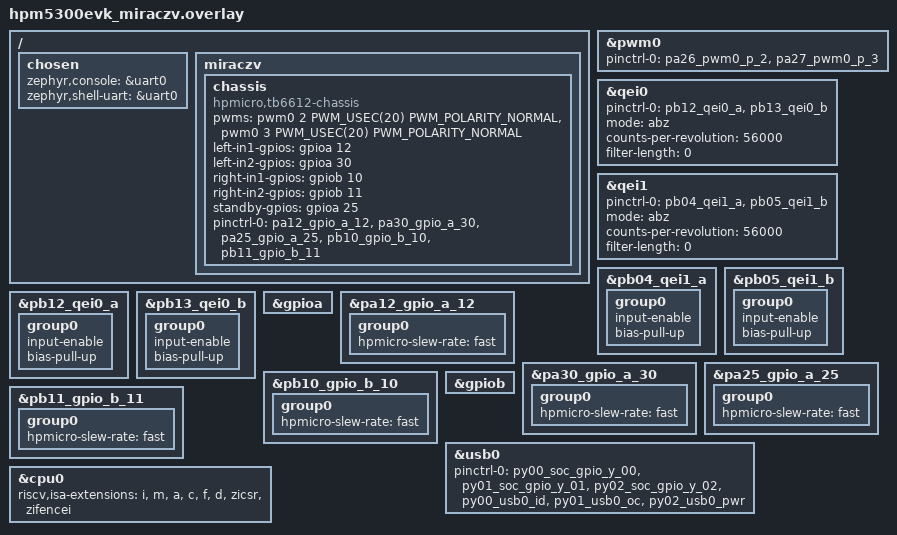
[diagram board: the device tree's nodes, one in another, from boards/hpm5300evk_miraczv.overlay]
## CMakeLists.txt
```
# Copyright (c) 2026 Cody Gu <gujiaqi@iscas.ac.cn>
#
# SPDX-License-Identifier: Apache-2.0

cmake_minimum_required(VERSION 3.20.0)

list(APPEND ZEPHYR_EXTRA_MODULES
  ${CMAKE_CURRENT_SOURCE_DIR}/module
)

list(APPEND DTS_ROOT
  ${CMAKE_CURRENT_SOURCE_DIR}/module
)

find_package(Zephyr REQUIRED HINTS $ENV{ZEPHYR_BASE})
project(MiracZV)

zephyr_include_directories(${CMAKE_CURRENT_SOURCE_DIR}/include)

target_sources(app PRIVATE
  src/main.c
  src/control/controller.c
  src/control/pid.c
  src/control/differential_drive.c
)

if(CONFIG_MIRACZV_MOTOR_TB6612)
  target_sources(app PRIVATE src/platform/tb6612.c)
endif()

if(CONFIG_MIRACZV_ENCODER)
  target_sources(app PRIVATE src/platform/qeiv2_backend.c)
endif()

if(CONFIG_MIRACZV_HID_HOST)
  target_sources(app PRIVATE
    src/platform/hid_controller.c
    src/platform/hid_report.c
  )
  target_include_directories(app PRIVATE ${ZEPHYR_BASE}/subsys/usb/host)
endif()
```

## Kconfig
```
# Copyright (c) 2026 Cody Gu <gujiaqi@iscas.ac.cn>
#
# SPDX-License-Identifier: Apache-2.0

mainmenu "MiracZV"

source "Kconfig.zephyr"

rsource "Kconfig.app"
```

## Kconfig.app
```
# Copyright (c) 2026 Cody Gu <gujiaqi@iscas.ac.cn>
#
# SPDX-License-Identifier: Apache-2.0

menu "MiracZV application"

config MIRACZV
	bool
	default y

config MIRACZV_MOTOR_TB6612
	bool "TB6612 motor controller"
	default y
	depends on PWM && GPIO

config MIRACZV_ENCODER
	bool "Generic encoder with QEIV2 backend"
	default y
	depends on QEIV2_HPMICRO
	depends on MIRACZV_MOTOR_TB6612

config MIRACZV_HID_HOST
	bool "USB HID host controller input"
	default y
	depends on USB_HOST_STACK && UHC_DRIVER

config MIRACZV_HID_LOG_LEVEL
	int "HID host log level"
	default 3
	range 0 4
	help
	  0 = off, 1 = error, 2 = warning, 3 = info, 4 = debug.

config MIRACZV_CONTROL_PERIOD_MS
	int "Closed-loop control period in milliseconds"
	default 10
	range 1 100

config MIRACZV_WHEEL_RADIUS_MM
	int "Wheel radius in millimeters"
	default 32
	range 1 1000

config MIRACZV_TRACK_WIDTH_MM
	int "Wheel track width in millimeters"
	default 150
	range 1 5000

config MIRACZV_WHEELBASE_MM
	int "Vehicle wheelbase in millimeters"
	default 300
	range 1 10000
	help
	  Reserved for chassis models that need front-to-rear axle spacing.
	  The current differential drive uses MIRACZV_TRACK_WIDTH_MM instead.

config MIRACZV_MAX_WHEEL_MPS
	int "Absolute maximum wheel speed in millimeters per second"
	default 2000
	range 1 100000

config MIRACZV_MAX_LINEAR_MPS
	int "Maximum remote-control linear speed in millimeters per second"
	default 500
	range 1 100000

config MIRACZV_MAX_ANGULAR_MRADPS
	int "Maximum remote-control yaw rate in milliradians per second"
	default 6667
	range 1 100000

config MIRACZV_COMMAND_TIMEOUT_MS
	int "Controller command timeout in milliseconds"
	default 1000
	range 100 10000

config MIRACZV_HID_AXIS_DEADZONE_PERMILLE
	int "HID gamepad axis dead zone in per mille"
	default 60
	range 0 500

choice MIRACZV_HID_RIGHT_STICK_AXES
	prompt "Preferred HID right-stick axis encoding"
	default MIRACZV_HID_RIGHT_STICK_Z_RZ
	help
	  Select the Generic Desktop axes normally used by the right stick.
	  MiracZV falls back to the other pair when the preference is absent.

config MIRACZV_HID_RIGHT_STICK_Z_RZ
	bool "Z and RZ axes"

config MIRACZV_HID_RIGHT_STICK_RX_RY
	bool "RX and RY axes"

endchoice

config MIRACZV_HID_INVERT_THROTTLE
	bool "Invert the right-stick throttle axis"
	default y
	help
	  Most HID gamepads report the vertical axis with its minimum at the
	  top. Enable this so pushing the right stick forward drives forward.

config MIRACZV_HID_INVERT_STEERING
	bool "Invert the right-stick steering axis"
	default y
	help
	  Standard HID gamepads report left as the axis minimum. Inverting this
	  axis maps left stick movement to positive yaw, which turns left.

config MIRACZV_HID_REPORT_TIMEOUT_MS
	int "HID interrupt transfer timeout in milliseconds"
	default 250
	range 20 5000

config MIRACZV_HID_RETRY_PERIOD_MS
	int "HID host retry period in milliseconds"
	default 1000
	range 100 10000

config MIRACZV_PWM_PERIOD_US
	int "Expected motor PWM period in microseconds"
	default 20
	range 1 20000
	help
	  Must match the period encoded in the chassis pwms devicetree property.
	  The PWM hardware uses the devicetree period directly.

endmenu
```

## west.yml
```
# SPDX-License-Identifier: Apache-2.0

manifest:
  version: "1.0"

  remotes:
    - name: zephyrproject-rtos
      url-base: https://github.com/zephyrproject-rtos
    - name: hpmicro
      url-base: https://github.com/hpmicro
    - name: discodyer
      url-base: https://github.com/discodyer

  defaults:
    remote: discodyer

  projects:
    - name: zephyr
      remote: zephyrproject-rtos
      revision: 41d10b59730406bbab4ca9f1fbbe9e96aafb4966
      import: true

    - name: hpm_sdk
      remote: hpmicro
      revision: ccc5ec467a047f3ea85cd2fa4565e91db7135a38
      path: modules/hal/hpm_sdk

    - name: hpm-zephyr
      revision: 10ea4c3f7fa7d6f69be9a9d86c77a51330eb7ef8
      path: modules/hpm-zephyr

  self:
    path: miraczv
```

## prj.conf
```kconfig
# Copyright (c) 2026 Cody Gu <gujiaqi@iscas.ac.cn>
#
# SPDX-License-Identifier: Apache-2.0

CONFIG_CONSOLE=y
CONFIG_SERIAL=y
CONFIG_UART_CONSOLE=y
CONFIG_GPIO=y
CONFIG_PWM=y
CONFIG_SENSOR=y
CONFIG_QEIV2_HPMICRO=y
CONFIG_MIRACZV_MOTOR_TB6612=y
CONFIG_MIRACZV_ENCODER=y
CONFIG_MIRACZV_HID_HOST=y

CONFIG_MIRACZV_WHEELBASE_MM=300
CONFIG_MIRACZV_TRACK_WIDTH_MM=150
CONFIG_MIRACZV_WHEEL_RADIUS_MM=32
CONFIG_MIRACZV_MAX_LINEAR_MPS=500
CONFIG_MIRACZV_MAX_ANGULAR_MRADPS=6667

# Right stick: horizontal steers, vertical controls forward/reverse.
CONFIG_MIRACZV_HID_RIGHT_STICK_Z_RZ=y
CONFIG_MIRACZV_HID_INVERT_THROTTLE=y
CONFIG_MIRACZV_HID_INVERT_STEERING=y

CONFIG_USB_HOST_STACK=y
CONFIG_HPMICRO_USB_ROLE_HOST=y
CONFIG_UHC_HPMICRO=y
CONFIG_UHC_BUF_COUNT=16
CONFIG_UHC_BUF_POOL_SIZE=2048
CONFIG_USBH_USB_DEVICE_HEAP=2048

CONFIG_CPP=n
CONFIG_FPU=y
CONFIG_FPU_SHARING=y
CONFIG_FLOAT_HARD=y
CONFIG_CBPRINTF_FP_SUPPORT=y
CONFIG_LOG=y
CONFIG_LOG_DEFAULT_LEVEL=3
CONFIG_LOG_MODE_MINIMAL=y
CONFIG_MAIN_STACK_SIZE=8192
CONFIG_SYSTEM_WORKQUEUE_STACK_SIZE=2048
CONFIG_HEAP_MEM_POOL_SIZE=16384
CONFIG_ASSERT=y
CONFIG_INIT_STACKS=y
CONFIG_STACK_SENTINEL=y
CONFIG_HW_STACK_PROTECTION=y
```

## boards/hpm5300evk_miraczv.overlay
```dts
/*
 * Copyright (c) 2026 Cody Gu <gujiaqi@iscas.ac.cn>
 * SPDX-License-Identifier: Apache-2.0
 */

#include <zephyr/dt-bindings/pwm/pwm.h>
#include <zephyr/dt-bindings/gpio/gpio.h>

/ {
	chosen {
		zephyr,console = &uart0;
		zephyr,shell-uart = &uart0;
	};

	miraczv {
		status = "okay";

		chassis: chassis {
			compatible = "hpmicro,tb6612-chassis";
			pwms = <&pwm0 2 PWM_USEC(20) PWM_POLARITY_NORMAL>,
			       <&pwm0 3 PWM_USEC(20) PWM_POLARITY_NORMAL>;
			left-in1-gpios = <&gpioa 12 GPIO_ACTIVE_HIGH>;
			left-in2-gpios = <&gpioa 30 GPIO_ACTIVE_HIGH>;
			right-in1-gpios = <&gpiob 10 GPIO_ACTIVE_HIGH>;
			right-in2-gpios = <&gpiob 11 GPIO_ACTIVE_HIGH>;
			standby-gpios = <&gpioa 25 GPIO_ACTIVE_HIGH>;
			pinctrl-0 = <&pa12_gpio_a_12 &pa30_gpio_a_30 &pa25_gpio_a_25
				     &pb10_gpio_b_10 &pb11_gpio_b_11>;
			pinctrl-names = "default";
		};
	};
};

&pwm0 {
	status = "okay";
	pinctrl-0 = <&pa26_pwm0_p_2 &pa27_pwm0_p_3>;
	pinctrl-names = "default";
};

&qei0 {
	status = "okay";
	pinctrl-0 = <&pb12_qei0_a &pb13_qei0_b>;
	pinctrl-names = "default";
	mode = "abz";
	counts-per-revolution = <56000>;
	filter-length = <0>;
};

&qei1 {
	status = "okay";
	pinctrl-0 = <&pb04_qei1_a &pb05_qei1_b>;
	pinctrl-names = "default";
	mode = "abz";
	counts-per-revolution = <56000>;
	filter-length = <0>;
};

&pb04_qei1_a {
	group0 {
		input-enable;
		bias-pull-up;
	};
};

&pb05_qei1_b {
	group0 {
		input-enable;
		bias-pull-up;
	};
};

&pb12_qei0_a {
	group0 {
		input-enable;
		bias-pull-up;
	};
};

&pb13_qei0_b {
	group0 {
		input-enable;
		bias-pull-up;
	};
};

&gpioa {
	status = "okay";
};

&pa12_gpio_a_12 {
	group0 {
		hpmicro-slew-rate = "fast";
	};
};

&pa30_gpio_a_30 {
	group0 {
		hpmicro-slew-rate = "fast";
	};
};

&pa25_gpio_a_25 {
	group0 {
		hpmicro-slew-rate = "fast";
	};
};

&pb10_gpio_b_10 {
	group0 {
		hpmicro-slew-rate = "fast";
	};
};

&pb11_gpio_b_11 {
	group0 {
		hpmicro-slew-rate = "fast";
	};
};

&gpiob {
	status = "okay";
};

&usb0 {
	status = "okay";
	pinctrl-0 = <&py00_soc_gpio_y_00 &py01_soc_gpio_y_01 &py02_soc_gpio_y_02
		     &py00_usb0_id &py01_usb0_oc &py02_usb0_pwr>;
};

&cpu0 {
	riscv,isa-extensions = "i", "m", "a", "c", "f", "d", "zicsr", "zifencei";
};
```

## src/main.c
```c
/*
 * Copyright (c) 2026 Cody Gu <gujiaqi@iscas.ac.cn>
 * SPDX-License-Identifier: Apache-2.0
 */

#include <miraczv/board.h>
#include <miraczv/control/controller.h>
#include <miraczv/control/differential_drive.h>
#ifdef CONFIG_MIRACZV_HID_HOST
#include <miraczv/platform/hid_controller.h>
#endif
#include <zephyr/kernel.h>
#include <zephyr/logging/log.h>

LOG_MODULE_REGISTER(miraczv, LOG_LEVEL_INF);

static struct miraczv_command last_command;
static int64_t last_command_ms;

static void command_timeout_check(int64_t now_ms)
{
	if (last_command.valid &&
	    ((now_ms - last_command_ms) > CONFIG_MIRACZV_COMMAND_TIMEOUT_MS)) {
		last_command.valid = false;
		miraczv_drive_stop();
		LOG_WRN("Controller command timeout, motors coasting");
	}
}

int main(void)
{
	const struct miraczv_chassis_config *chassis = miraczv_chassis_config_get();
	struct miraczv_drive_config drive_config = {
		.wheel_radius_m = CONFIG_MIRACZV_WHEEL_RADIUS_MM / 1000.0f,
		.track_width_m = CONFIG_MIRACZV_TRACK_WIDTH_MM / 1000.0f,
		.max_wheel_speed_mps = CONFIG_MIRACZV_MAX_WHEEL_MPS / 1000.0f,
	};
	struct miraczv_command command;
	int ret;

	for (size_t i = 0; i < MIRACZV_WHEEL_COUNT; ++i) {
		drive_config.pid[i] = (struct miraczv_pid){
			.kp = 1.1f,
			.ki = 2.0f,
			.kd = 0.0f,
			.output_min = -1.0f,
			.output_max = 1.0f,
		};
	}

	if (!device_is_ready(chassis->encoder[MIRACZV_WHEEL_LEFT].dev) ||
	    !device_is_ready(chassis->encoder[MIRACZV_WHEEL_RIGHT].dev)) {
		LOG_ERR("Encoder device not ready");
		return 0;
	}

	ret = miraczv_chassis_init(chassis);
	if (ret != 0) {
		LOG_ERR("Chassis initialization failed: %d", ret);
		return 0;
	}

	ret = miraczv_drive_init(&drive_config);
	if (ret != 0) {
		LOG_ERR("Drive initialization failed: %d", ret);
		return 0;
	}

#ifdef CONFIG_MIRACZV_HID_HOST
	ret = miraczv_controller_register(&miraczv_hid_controller_ops);
	if (ret == 0) {
		ret = miraczv_controller_activate(&miraczv_hid_controller_ops);
	}
	if (ret == 0) {
		ret = miraczv_controller_init();
	}
	if (ret != 0) {
		LOG_ERR("HID controller initialization failed: %d", ret);
	}
#endif

	LOG_INF("MiracZV ready: controller=%s",
		miraczv_controller_name() != NULL ? miraczv_controller_name() : "none");
	last_command_ms = k_uptime_get();

	while (true) {
		int64_t now_ms = k_uptime_get();

		command = (struct miraczv_command){0};
		ret = miraczv_controller_poll(&command);
		if (ret == 0 && command.valid) {
			last_command = command;
			last_command_ms = now_ms;
			miraczv_drive_set_command(&command);
		} else if (ret != -EAGAIN && ret != -ENODEV && ret != -ENODATA) {
			LOG_DBG("Controller poll failed: %d", ret);
		}

		command_timeout_check(now_ms);
		miraczv_drive_control_step(now_ms);
		k_sleep(K_MSEC(CONFIG_MIRACZV_CONTROL_PERIOD_MS));
	}
}
```
